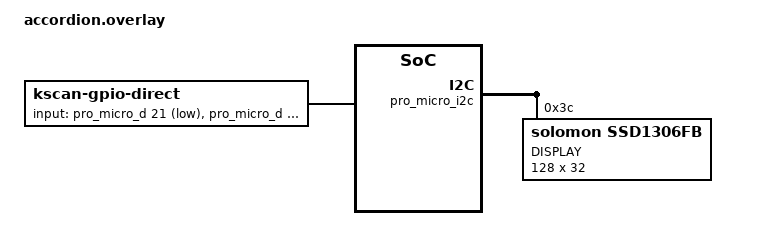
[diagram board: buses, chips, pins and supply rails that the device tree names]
/*
  * Copyright (c) 2024 Petko Yotov pmwiki.org/petko for Accordion
  *
  * SPDX-License-Identifier: MIT
  */

#include <dt-bindings/zmk/matrix_transform.h>

&pro_micro_i2c {
  status = "okay";

  oled: ssd1306@3c {
    compatible = "solomon,ssd1306fb";
    reg = <0x3c>;
    label = "DISPLAY";
    width = <128>;
    height = <32>;
    segment-offset = <0>;
    page-offset = <0>;
    display-offset = <0>;
    multiplex-ratio = <31>;
    segment-remap;
    com-invdir;
    com-sequential;
    prechargep = <0x22>;
    inversion-on;
  };
};

/ {
  chosen {
    zmk,kscan = &kscan0;
    zephyr,display = &oled;
  };

  kscan0: kscan_0 {
    compatible = "zmk,kscan-gpio-direct";

    label = "KSCAN";

    input-gpios
      = <&pro_micro_d 21 (GPIO_ACTIVE_LOW | GPIO_PULL_UP)>
      , <&pro_micro_d 15 (GPIO_ACTIVE_LOW | GPIO_PULL_UP)>
      , <&pro_micro_d  5 (GPIO_ACTIVE_LOW | GPIO_PULL_UP)>
      
      , <&pro_micro_d  7 (GPIO_ACTIVE_LOW | GPIO_PULL_UP)>
      , <&pro_micro_d  4 (GPIO_ACTIVE_LOW | GPIO_PULL_UP)>
      , <&pro_micro_d  1 (GPIO_ACTIVE_LOW | GPIO_PULL_UP)>
      
      
      , <&pro_micro_d 20 (GPIO_ACTIVE_LOW | GPIO_PULL_UP)>
      , <&pro_micro_d 18 (GPIO_ACTIVE_LOW | GPIO_PULL_UP)>
      , <&pro_micro_d 14 (GPIO_ACTIVE_LOW | GPIO_PULL_UP)>
      
      , <&pro_micro_d  9 (GPIO_ACTIVE_LOW | GPIO_PULL_UP)>
      , <&pro_micro_d  3 (GPIO_ACTIVE_LOW | GPIO_PULL_UP)>
      , <&pro_micro_d  0 (GPIO_ACTIVE_LOW | GPIO_PULL_UP)>
      
      
      , <&pro_micro_d 19 (GPIO_ACTIVE_LOW | GPIO_PULL_UP)>
      , <&pro_micro_d 16 (GPIO_ACTIVE_LOW | GPIO_PULL_UP)>

/*
, <&pro_micro_d 10 (GPIO_ACTIVE_LOW | GPIO_PULL_UP)>
, <&pro_micro_d  6 (GPIO_ACTIVE_LOW | GPIO_PULL_UP)>
*/

      , <&pro_micro_d  8 (GPIO_ACTIVE_LOW | GPIO_PULL_UP)>
      , <&pro_micro_d  2 (GPIO_ACTIVE_LOW | GPIO_PULL_UP)>
      
      ;
  };
};

